AUTOSAR XML (schema 4-2-2)
package /Components
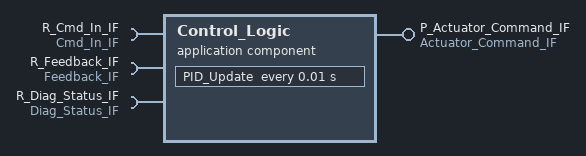
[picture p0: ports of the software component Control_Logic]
  application sw component type Control_Logic
    provide port P_Actuator_Command_IF: provided-interface=Actuator_Command_IF
    require port R_Cmd_In_IF: required-interface=Cmd_In_IF
    require port R_Feedback_IF: required-interface=Feedback_IF
    require port R_Diag_Status_IF: required-interface=Diag_Status_IF
    behavior Control_Logic_IB
      init event Control_Logic_Init: start-on-event=PID_Update
      timing event Control_Logic_Cycle: start-on-event=PID_Update, period=0.01
      runnable PID_Update: minimum-start-interval=0.01
        data-receive-point-by-arguments:
          9 x access:
            VA_RX_m1_speed_cmd: accessed-variable=R_Cmd_In_IF.m1_speed_cmd
            VA_RX_m1_pos_cmd: accessed-variable=R_Cmd_In_IF.m1_pos_cmd
            VA_RX_m2_speed_cmd: accessed-variable=R_Cmd_In_IF.m2_speed_cmd
            VA_RX_m2_pos_cmd: accessed-variable=R_Cmd_In_IF.m2_pos_cmd
            VA_RX_m1_speed_meas: accessed-variable=R_Feedback_IF.m1_speed_meas
            VA_RX_m1_pos_meas: accessed-variable=R_Feedback_IF.m1_pos_meas
            VA_RX_m2_speed_meas: accessed-variable=R_Feedback_IF.m2_speed_meas
            VA_RX_m2_pos_meas: accessed-variable=R_Feedback_IF.m2_pos_meas
            VA_RX_diag_status: accessed-variable=R_Diag_Status_IF.diag_status
        data-send-points:
          access VA_TX_m1_pwm_duty: accessed-variable=P_Actuator_Command_IF.m1_pwm_duty
          access VA_TX_m2_pwm_duty: accessed-variable=P_Actuator_Command_IF.m2_pwm_duty
